# ESP32-S31 register map
Vendor: ESPRESSIF SYSTEMS (SHANGHAI) CO., LTD.; Series: ESP32 S-Series; File version: 1
CPU: RV32IMAFC r0p0, little endian, no MPU, FPU, 0 interrupt priority bits
Address unit: 32 bits
Registers are 32-bit, read-write, reset 0x0 unless marked. A register's access mark holds for its fields unless they carry their own. Offsets are from the block's base; [hi:lo] are bit positions; {n}, {i} and the like mark numbered series.

## CNNT_IO_MUX — CNNT_IO_MUX Peripheral
Base 0x20588000
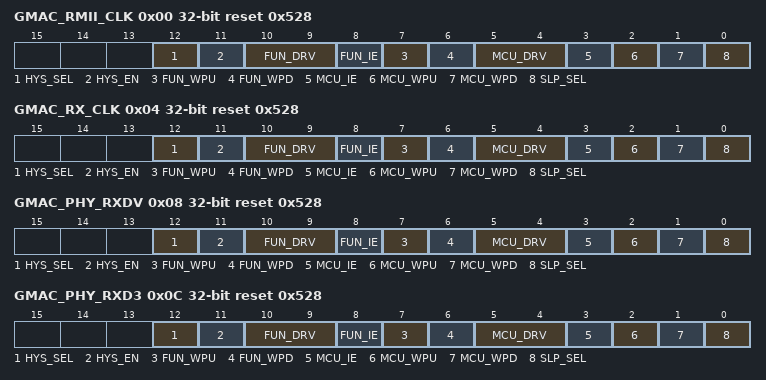
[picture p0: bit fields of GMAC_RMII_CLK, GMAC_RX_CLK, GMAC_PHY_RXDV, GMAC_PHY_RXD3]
0x00 GMAC_RMII_CLK reset 0x528 — GMAC IO MUX configuration register for GMAC_RMII_CLK
  [12] HYS_SEL — Configures to choose the signal for enabling the hysteresis function for GMAC_RMII_CLK. \\ 0: Choose the output enable signal of eFuse\\ 1: Choose the output enable signal of CNNT_IO_MUX_GMAC_RMII_CLK_HYS_EN\\
  [11] HYS_EN — Configures whether or not to enable the hysteresis function of the pin when CNNT_IO_MUX_GMAC_RMII_CLK_HYS_SEL is set to 1.\\ 0: Disable\\ 1: Enable\\
  [10:9] FUN_DRV — Configures the drive strength of GMAC_RMII_CLK. \\ 0: ~5 mA\\ 1: ~10 mA\\ 2: ~20 mA\\ 3: ~40 mA\\
  [8] FUN_IE — Configures whether or not to enable input of GMAC_RMII_CLK.\\ 0: Disable\\ 1: Enable\\
  [7] FUN_WPU — Configures whether or not enable pull-up resistor of GMAC_RMII_CLK.\\ 0: Disable\\ 1: Enable\\
  [6] FUN_WPD — Configures whether or not to enable pull-down resistor of GMAC_RMII_CLK.\\ 0: Disable\\ 1: Enable\\
  [5:4] MCU_DRV — Configures the drive strength of GMAC_RMII_CLK during sleep mode. \\ 0: ~5 mA\\ 1: ~10 mA\\ 2: ~20 mA\\ 3: ~40 mA\\
  [3] MCU_IE — Configures whether or not to enable the input of GMAC_RMII_CLK during sleep mode.\\ 0: Disable\\ 1: Enable\\
  [2] MCU_WPU — Configures whether or not to enable pull-up resistor of GMAC_RMII_CLK during sleep mode. \\ 0: Disable\\ 1: Enable\\
  [1] MCU_WPD — Configure whether or not to enable pull-down resistor of GMAC_RMII_CLK in sleep mode.\\ 0: Disable\\ 1: Enable\\
  [0] SLP_SEL — Configures whether or not to enter sleep mode for GMAC_RMII_CLK.\\ 0: Not enter\\ 1: Enter\\
0x04 GMAC_RX_CLK reset 0x528 — GMAC IO MUX configuration register for GMAC_RX_CLK
  [12] HYS_SEL — Configures to choose the signal for enabling the hysteresis function for GMAC_RX_CLK. \\ 0: Choose the output enable signal of eFuse\\ 1: Choose the output enable signal of CNNT_IO_MUX_GMAC_RX_CLK_HYS_EN\\
  [11] HYS_EN — Configures whether or not to enable the hysteresis function of the pin when CNNT_IO_MUX_GMAC_RX_CLK_HYS_SEL is set to 1.\\ 0: Disable\\ 1: Enable\\
  [10:9] FUN_DRV — Configures the drive strength of GMAC_RX_CLK. \\ 0: ~5 mA\\ 1: ~10 mA\\ 2: ~20 mA\\ 3: ~40 mA\\
  [8] FUN_IE — Configures whether or not to enable input of GMAC_RX_CLK.\\ 0: Disable\\ 1: Enable\\
  [7] FUN_WPU — Configures whether or not enable pull-up resistor of GMAC_RX_CLK.\\ 0: Disable\\ 1: Enable\\
  [6] FUN_WPD — Configures whether or not to enable pull-down resistor of GMAC_RX_CLK.\\ 0: Disable\\ 1: Enable\\
  [5:4] MCU_DRV — Configures the drive strength of GMAC_RX_CLK during sleep mode. \\ 0: ~5 mA\\ 1: ~10 mA\\ 2: ~20 mA\\ 3: ~40 mA\\
  [3] MCU_IE — Configures whether or not to enable the input of GMAC_RX_CLK during sleep mode.\\ 0: Disable\\ 1: Enable\\
  [2] MCU_WPU — Configures whether or not to enable pull-up resistor of GMAC_RX_CLK during sleep mode. \\ 0: Disable\\ 1: Enable\\
  [1] MCU_WPD — Configure whether or not to enable pull-down resistor of GMAC_RX_CLK in sleep mode.\\ 0: Disable\\ 1: Enable\\
  [0] SLP_SEL — Configures whether or not to enter sleep mode for GMAC_RX_CLK.\\ 0: Not enter\\ 1: Enter\\
0x08 GMAC_PHY_RXDV reset 0x528 — GMAC IO MUX configuration register for GMAC_PHY_RXDV
  [12] HYS_SEL — Configures to choose the signal for enabling the hysteresis function for GMAC_PHY_RXDV. \\ 0: Choose the output enable signal of eFuse\\ 1: Choose the output enable signal of CNNT_IO_MUX_GMAC_PHY_RXDV_HYS_EN\\
  [11] HYS_EN — Configures whether or not to enable the hysteresis function of the pin when CNNT_IO_MUX_GMAC_PHY_RXDV_HYS_SEL is set to 1.\\ 0: Disable\\ 1: Enable\\
  [10:9] FUN_DRV — Configures the drive strength of GMAC_PHY_RXDV. \\ 0: ~5 mA\\ 1: ~10 mA\\ 2: ~20 mA\\ 3: ~40 mA\\
  [8] FUN_IE — Configures whether or not to enable input of GMAC_PHY_RXDV.\\ 0: Disable\\ 1: Enable\\
  [7] FUN_WPU — Configures whether or not enable pull-up resistor of GMAC_PHY_RXDV.\\ 0: Disable\\ 1: Enable\\
  [6] FUN_WPD — Configures whether or not to enable pull-down resistor of GMAC_PHY_RXDV.\\ 0: Disable\\ 1: Enable\\
  [5:4] MCU_DRV — Configures the drive strength of GMAC_PHY_RXDV during sleep mode. \\ 0: ~5 mA\\ 1: ~10 mA\\ 2: ~20 mA\\ 3: ~40 mA\\
  [3] MCU_IE — Configures whether or not to enable the input of GMAC_PHY_RXDV during sleep mode.\\ 0: Disable\\ 1: Enable\\
  [2] MCU_WPU — Configures whether or not to enable pull-up resistor of GMAC_PHY_RXDV during sleep mode. \\ 0: Disable\\ 1: Enable\\
  [1] MCU_WPD — Configure whether or not to enable pull-down resistor of GMAC_PHY_RXDV in sleep mode.\\ 0: Disable\\ 1: Enable\\
  [0] SLP_SEL — Configures whether or not to enter sleep mode for GMAC_PHY_RXDV.\\ 0: Not enter\\ 1: Enter\\
0x0C GMAC_PHY_RXD3 reset 0x528 — GMAC IO MUX configuration register for GMAC_PHY_RXD3
  [12] HYS_SEL — Configures to choose the signal for enabling the hysteresis function for GMAC_PHY_RXD3. \\ 0: Choose the output enable signal of eFuse\\ 1: Choose the output enable signal of CNNT_IO_MUX_GMAC_PHY_RXD3_HYS_EN\\
  [11] HYS_EN — Configures whether or not to enable the hysteresis function of the pin when CNNT_IO_MUX_GMAC_PHY_RXD3_HYS_SEL is set to 1.\\ 0: Disable\\ 1: Enable\\
  [10:9] FUN_DRV — Configures the drive strength of GMAC_PHY_RXD3. \\ 0: ~5 mA\\ 1: ~10 mA\\ 2: ~20 mA\\ 3: ~40 mA\\
  [8] FUN_IE — Configures whether or not to enable input of GMAC_PHY_RXD3.\\ 0: Disable\\ 1: Enable\\
  [7] FUN_WPU — Configures whether or not enable pull-up resistor of GMAC_PHY_RXD3.\\ 0: Disable\\ 1: Enable\\
  [6] FUN_WPD — Configures whether or not to enable pull-down resistor of GMAC_PHY_RXD3.\\ 0: Disable\\ 1: Enable\\
  [5:4] MCU_DRV — Configures the drive strength of GMAC_PHY_RXD3 during sleep mode. \\ 0: ~5 mA\\ 1: ~10 mA\\ 2: ~20 mA\\ 3: ~40 mA\\
  [3] MCU_IE — Configures whether or not to enable the input of GMAC_PHY_RXD3 during sleep mode.\\ 0: Disable\\ 1: Enable\\
  [2] MCU_WPU — Configures whether or not to enable pull-up resistor of GMAC_PHY_RXD3 during sleep mode. \\ 0: Disable\\ 1: Enable\\
  [1] MCU_WPD — Configure whether or not to enable pull-down resistor of GMAC_PHY_RXD3 in sleep mode.\\ 0: Disable\\ 1: Enable\\
  [0] SLP_SEL — Configures whether or not to enter sleep mode for GMAC_PHY_RXD3.\\ 0: Not enter\\ 1: Enter\\
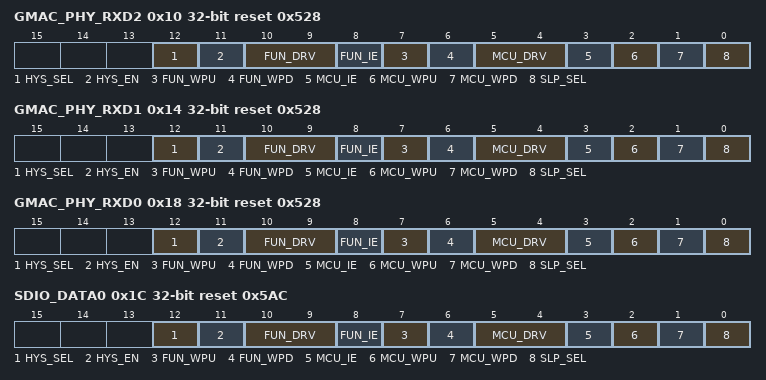
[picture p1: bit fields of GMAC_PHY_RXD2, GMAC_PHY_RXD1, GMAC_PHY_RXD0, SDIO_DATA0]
0x10 GMAC_PHY_RXD2 reset 0x528 — GMAC IO MUX configuration register for GMAC_PHY_RXD2
  [12] HYS_SEL — Configures to choose the signal for enabling the hysteresis function for GMAC_PHY_RXD2. \\ 0: Choose the output enable signal of eFuse\\ 1: Choose the output enable signal of CNNT_IO_MUX_GMAC_PHY_RXD2_HYS_EN\\
  [11] HYS_EN — Configures whether or not to enable the hysteresis function of the pin when CNNT_IO_MUX_GMAC_PHY_RXD2_HYS_SEL is set to 1.\\ 0: Disable\\ 1: Enable\\
  [10:9] FUN_DRV — Configures the drive strength of GMAC_PHY_RXD2. \\ 0: ~5 mA\\ 1: ~10 mA\\ 2: ~20 mA\\ 3: ~40 mA\\
  [8] FUN_IE — Configures whether or not to enable input of GMAC_PHY_RXD2.\\ 0: Disable\\ 1: Enable\\
  [7] FUN_WPU — Configures whether or not enable pull-up resistor of GMAC_PHY_RXD2.\\ 0: Disable\\ 1: Enable\\
  [6] FUN_WPD — Configures whether or not to enable pull-down resistor of GMAC_PHY_RXD2.\\ 0: Disable\\ 1: Enable\\
  [5:4] MCU_DRV — Configures the drive strength of GMAC_PHY_RXD2 during sleep mode. \\ 0: ~5 mA\\ 1: ~10 mA\\ 2: ~20 mA\\ 3: ~40 mA\\
  [3] MCU_IE — Configures whether or not to enable the input of GMAC_PHY_RXD2 during sleep mode.\\ 0: Disable\\ 1: Enable\\
  [2] MCU_WPU — Configures whether or not to enable pull-up resistor of GMAC_PHY_RXD2 during sleep mode. \\ 0: Disable\\ 1: Enable\\
  [1] MCU_WPD — Configure whether or not to enable pull-down resistor of GMAC_PHY_RXD2 in sleep mode.\\ 0: Disable\\ 1: Enable\\
  [0] SLP_SEL — Configures whether or not to enter sleep mode for GMAC_PHY_RXD2.\\ 0: Not enter\\ 1: Enter\\
0x14 GMAC_PHY_RXD1 reset 0x528 — GMAC IO MUX configuration register for GMAC_PHY_RXD1
  [12] HYS_SEL — Configures to choose the signal for enabling the hysteresis function for GMAC_PHY_RXD1. \\ 0: Choose the output enable signal of eFuse\\ 1: Choose the output enable signal of CNNT_IO_MUX_GMAC_PHY_RXD1_HYS_EN\\
  [11] HYS_EN — Configures whether or not to enable the hysteresis function of the pin when CNNT_IO_MUX_GMAC_PHY_RXD1_HYS_SEL is set to 1.\\ 0: Disable\\ 1: Enable\\
  [10:9] FUN_DRV — Configures the drive strength of GMAC_PHY_RXD1. \\ 0: ~5 mA\\ 1: ~10 mA\\ 2: ~20 mA\\ 3: ~40 mA\\
  [8] FUN_IE — Configures whether or not to enable input of GMAC_PHY_RXD1.\\ 0: Disable\\ 1: Enable\\
  [7] FUN_WPU — Configures whether or not enable pull-up resistor of GMAC_PHY_RXD1.\\ 0: Disable\\ 1: Enable\\
  [6] FUN_WPD — Configures whether or not to enable pull-down resistor of GMAC_PHY_RXD1.\\ 0: Disable\\ 1: Enable\\
  [5:4] MCU_DRV — Configures the drive strength of GMAC_PHY_RXD1 during sleep mode. \\ 0: ~5 mA\\ 1: ~10 mA\\ 2: ~20 mA\\ 3: ~40 mA\\
  [3] MCU_IE — Configures whether or not to enable the input of GMAC_PHY_RXD1 during sleep mode.\\ 0: Disable\\ 1: Enable\\
  [2] MCU_WPU — Configures whether or not to enable pull-up resistor of GMAC_PHY_RXD1 during sleep mode. \\ 0: Disable\\ 1: Enable\\
  [1] MCU_WPD — Configure whether or not to enable pull-down resistor of GMAC_PHY_RXD1 in sleep mode.\\ 0: Disable\\ 1: Enable\\
  [0] SLP_SEL — Configures whether or not to enter sleep mode for GMAC_PHY_RXD1.\\ 0: Not enter\\ 1: Enter\\
0x18 GMAC_PHY_RXD0 reset 0x528 — GMAC IO MUX configuration register for GMAC_PHY_RXD0
  [12] HYS_SEL — Configures to choose the signal for enabling the hysteresis function for GMAC_PHY_RXD0. \\ 0: Choose the output enable signal of eFuse\\ 1: Choose the output enable signal of CNNT_IO_MUX_GMAC_PHY_RXD0_HYS_EN\\
  [11] HYS_EN — Configures whether or not to enable the hysteresis function of the pin when CNNT_IO_MUX_GMAC_PHY_RXD0_HYS_SEL is set to 1.\\ 0: Disable\\ 1: Enable\\
  [10:9] FUN_DRV — Configures the drive strength of GMAC_PHY_RXD0. \\ 0: ~5 mA\\ 1: ~10 mA\\ 2: ~20 mA\\ 3: ~40 mA\\
  [8] FUN_IE — Configures whether or not to enable input of GMAC_PHY_RXD0.\\ 0: Disable\\ 1: Enable\\
  [7] FUN_WPU — Configures whether or not enable pull-up resistor of GMAC_PHY_RXD0.\\ 0: Disable\\ 1: Enable\\
  [6] FUN_WPD — Configures whether or not to enable pull-down resistor of GMAC_PHY_RXD0.\\ 0: Disable\\ 1: Enable\\
  [5:4] MCU_DRV — Configures the drive strength of GMAC_PHY_RXD0 during sleep mode. \\ 0: ~5 mA\\ 1: ~10 mA\\ 2: ~20 mA\\ 3: ~40 mA\\
  [3] MCU_IE — Configures whether or not to enable the input of GMAC_PHY_RXD0 during sleep mode.\\ 0: Disable\\ 1: Enable\\
  [2] MCU_WPU — Configures whether or not to enable pull-up resistor of GMAC_PHY_RXD0 during sleep mode. \\ 0: Disable\\ 1: Enable\\
  [1] MCU_WPD — Configure whether or not to enable pull-down resistor of GMAC_PHY_RXD0 in sleep mode.\\ 0: Disable\\ 1: Enable\\
  [0] SLP_SEL — Configures whether or not to enter sleep mode for GMAC_PHY_RXD0.\\ 0: Not enter\\ 1: Enter\\
0x1C SDIO_DATA0 reset 0x5AC — SDIO IO MUX configuration register for SDIO_DATA0
  [12] HYS_SEL — Configures to choose the signal for enabling the hysteresis function for SDIO_DATA0. \\ 0: Choose the output enable signal of eFuse\\ 1: Choose the output enable signal of CNNT_IO_MUX_SDIO_DATA0_HYS_EN\\
  [11] HYS_EN — Configures whether or not to enable the hysteresis function of the pin when CNNT_IO_MUX_SDIO_DATA0_HYS_SEL is set to 1.\\ 0: Disable\\ 1: Enable\\
  [10:9] FUN_DRV — Configures the drive strength of SDIO_DATA0. \\ 0: ~5 mA\\ 1: ~10 mA\\ 2: ~20 mA\\ 3: ~40 mA\\
  [8] FUN_IE — Configures whether or not to enable input of SDIO_DATA0.\\ 0: Disable\\ 1: Enable\\
  [7] FUN_WPU — Configures whether or not enable pull-up resistor of SDIO_DATA0.\\ 0: Disable\\ 1: Enable\\
  [6] FUN_WPD — Configures whether or not to enable pull-down resistor of SDIO_DATA0\\ 0: Disable\\ 1: Enable\\
  [5:4] MCU_DRV — Configures the drive strength of SDIO_DATA0 during sleep mode. \\ 0: ~5 mA\\ 1: ~10 mA\\ 2: ~20 mA\\ 3: ~40 mA\\
  [3] MCU_IE — Configures whether or not to enable the input of SDIO_DATA0 during sleep mode.\\ 0: Disable\\ 1: Enable\\
  [2] MCU_WPU — Configures whether or not to enable pull-up resistor of SDIO_DATA0 during sleep mode. \\ 0: Disable\\ 1: Enable\\
  [1] MCU_WPD — Configure whether or not to enable pull-down resistor of SDIO_DATA0 in sleep mode.\\ 0: Disable\\ 1: Enable\\
  [0] SLP_SEL — Configures whether or not to enter sleep mode for SDIO_DATA0.\\ 0: Not enter\\ 1: Enter\\
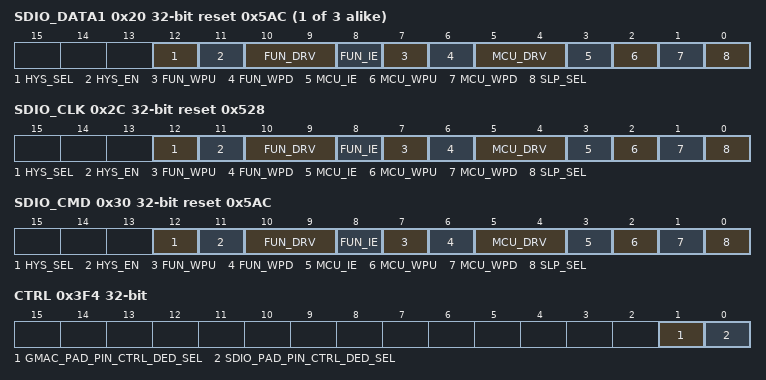
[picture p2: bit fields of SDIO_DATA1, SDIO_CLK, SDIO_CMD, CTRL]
{0x1C+4i} SDIO_DATA{i} reset 0x5AC (i=1..3) — SDIO IO MUX configuration register for SDIO_DATA{i}
  [12] HYS_SEL — Configures to choose the signal for enabling the hysteresis function for SDIO_DATA{i}. \\ 0: Choose the output enable signal of eFuse\\ 1: Choose the output enable signal of CNNT_IO_MUX_SDIO_DATA{i}_HYS_EN\\
  [11] HYS_EN — Configures whether or not to enable the hysteresis function of the pin when CNNT_IO_MUX_SDIO_DATA{i}_HYS_SEL is set to 1.\\ 0: Disable\\ 1: Enable\\
  [10:9] FUN_DRV — Configures the drive strength of SDIO_DATA{i}. \\ 0: ~5 mA\\ 1: ~10 mA\\ 2: ~20 mA\\ 3: ~40 mA\\
  [8] FUN_IE — Configures whether or not to enable input of SDIO_DATA{i}.\\ 0: Disable\\ 1: Enable\\
  [7] FUN_WPU — Configures whether or not enable pull-up resistor of SDIO_DATA{i}.\\ 0: Disable\\ 1: Enable\\
  [6] FUN_WPD — Configures whether or not to enable pull-down resistor of SDIO_DATA{i}.\\ 0: Disable\\ 1: Enable\\
  [5:4] MCU_DRV — Configures the drive strength of SDIO_DATA{i} during sleep mode. \\ 0: ~5 mA\\ 1: ~10 mA\\ 2: ~20 mA\\ 3: ~40 mA\\
  [3] MCU_IE — Configures whether or not to enable the input of SDIO_DATA{i} during sleep mode.\\ 0: Disable\\ 1: Enable\\
  [2] MCU_WPU — Configures whether or not to enable pull-up resistor of SDIO_DATA{i} during sleep mode. \\ 0: Disable\\ 1: Enable\\
  [1] MCU_WPD — Configure whether or not to enable pull-down resistor of SDIO_DATA{i} in sleep mode.\\ 0: Disable\\ 1: Enable\\
  [0] SLP_SEL — Configures whether or not to enter sleep mode for SDIO_DATA{i}.\\ 0: Not enter\\ 1: Enter\\
0x2C SDIO_CLK reset 0x528 — SDIO IO MUX configuration register for SDIO_CLK
  [12] HYS_SEL — Configures to choose the signal for enabling the hysteresis function for SDIO_CLK. \\ 0: Choose the output enable signal of eFuse\\ 1: Choose the output enable signal of CNNT_IO_MUX_SDIO_CLK_HYS_EN\\
  [11] HYS_EN — Configures whether or not to enable the hysteresis function of the pin when CNNT_IO_MUX_SDIO_CLK_HYS_SEL is set to 1.\\ 0: Disable\\ 1: Enable\\
  [10:9] FUN_DRV — Configures the drive strength of SDIO_CLK. \\ 0: ~5 mA\\ 1: ~10 mA\\ 2: ~20 mA\\ 3: ~40 mA\\
  [8] FUN_IE — Configures whether or not to enable input of SDIO_CLK.\\ 0: Disable\\ 1: Enable\\
  [7] FUN_WPU — Configures whether or not enable pull-up resistor of SDIO_CLK.\\ 0: Disable\\ 1: Enable\\
  [6] FUN_WPD — Configures whether or not to enable pull-down resistor of SDIO_CLK.\\ 0: Disable\\ 1: Enable\\
  [5:4] MCU_DRV — Configures the drive strength of SDIO_CLK during sleep mode. \\ 0: ~5 mA\\ 1: ~10 mA\\ 2: ~20 mA\\ 3: ~40 mA\\
  [3] MCU_IE — Configures whether or not to enable the input of SDIO_CLK during sleep mode.\\ 0: Disable\\ 1: Enable\\
  [2] MCU_WPU — Configures whether or not to enable pull-up resistor of SDIO_CLK during sleep mode. \\ 0: Disable\\ 1: Enable\\
  [1] MCU_WPD — Configure whether or not to enable pull-down resistor of SDIO_CLK in sleep mode.\\ 0: Disable\\ 1: Enable\\
  [0] SLP_SEL — Configures whether or not to enter sleep mode for SDIO_CLK.\\ 0: Not enter\\ 1: Enter\\
0x30 SDIO_CMD reset 0x5AC — SDIO IO MUX configuration register for SDIO_CMD
  [12] HYS_SEL — Configures to choose the signal for enabling the hysteresis function for SDIO_CMD. \\ 0: Choose the output enable signal of eFuse\\ 1: Choose the output enable signal of CNNT_IO_MUX_SDIO_CMD_HYS_EN\\
  [11] HYS_EN — Configures whether or not to enable the hysteresis function of the pin when CNNT_IO_MUX_SDIO_CMD_HYS_SEL is set to 1.\\ 0: Disable\\ 1: Enable\\
  [10:9] FUN_DRV — Configures the drive strength of SDIO_CMD. \\ 0: ~5 mA\\ 1: ~10 mA\\ 2: ~20 mA\\ 3: ~40 mA\\
  [8] FUN_IE — Configures whether or not to enable input of SDIO_CMD.\\ 0: Disable\\ 1: Enable\\
  [7] FUN_WPU — Configures whether or not enable pull-up resistor of SDIO_CMD.\\ 0: Disable\\ 1: Enable\\
  [6] FUN_WPD — Configures whether or not to enable pull-down resistor of SDIO_CMD.\\ 0: Disable\\ 1: Enable\\
  [5:4] MCU_DRV — Configures the drive strength of SDIO_CMD during sleep mode. \\ 0: ~5 mA\\ 1: ~10 mA\\ 2: ~20 mA\\ 3: ~40 mA\\
  [3] MCU_IE — Configures whether or not to enable the input of SDIO_CMD during sleep mode.\\ 0: Disable\\ 1: Enable\\
  [2] MCU_WPU — Configures whether or not to enable pull-up resistor of SDIO_CMD during sleep mode. \\ 0: Disable\\ 1: Enable\\
  [1] MCU_WPD — Configure whether or not to enable pull-down resistor of SDIO_CMD in sleep mode.\\ 0: Disable\\ 1: Enable\\
  [0] SLP_SEL — Configures whether or not to enter sleep mode for SDIO_CMD.\\ 0: Not enter\\ 1: Enter\\
0x3F4 CTRL — SDIO IO MUX configuration register for ctrl sel
  [1] GMAC_PAD_PIN_CTRL_DED_SEL — Configures whether or not to use dedicated ctrl signals for GMAC PAD.\\ 0: Not use dedicated ctrl signals\\ 1: Use dedicated ctrl signals\\
  [0] SDIO_PAD_PIN_CTRL_DED_SEL — Configures whether or not to use dedicated ctrl signals for SDIO PAD.\\ 0: Not use dedicated ctrl signals\\ 1: Use dedicated ctrl signals\\
0x3F8 CLOCK_GATE reset 0x1 — CNNT_IO_MUX clock gate register
  [0] CLK_EN — Configures whether or not to enable clock gate.\\ 0: Not enable\\ 1: Enable, the clock is free running. \\
0x3FC DATE reset 0x2509120 — Version control register
  [27:0] REG_DATE
